VERSION ""

NS_ :

BS_:

BU_:

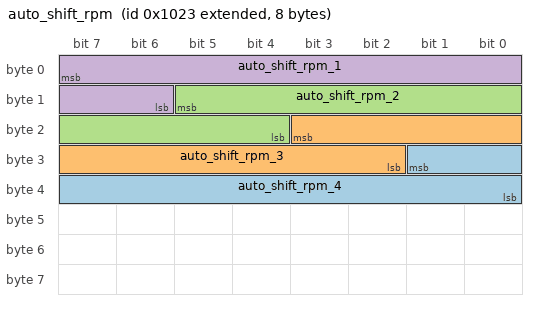
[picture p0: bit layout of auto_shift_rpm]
BO_ 2147487779 auto_shift_rpm: 8 Vector__XXX
 SG_ auto_shift_rpm_4 : 25|10@0+ (12,10000) [10000|22276] "RPM" Vector__XXX
 SG_ auto_shift_rpm_3 : 19|10@0+ (12,10000) [10000|22276] "RPM" Vector__XXX
 SG_ auto_shift_rpm_2 : 13|10@0+ (12,10000) [10000|22276] "RPM" Vector__XXX
 SG_ auto_shift_rpm_1 : 7|10@0+ (12,10000) [10000|22276] "RPM" Vector__XXX

BO_ 2147487776 servo: 5 Vector__XXX
 SG_ servo_pot : 27|12@0+ (0.00122100122,0) [0|0] "v" Vector__XXX
 SG_ servo_position : 23|12@0+ (1,0) [0|0] "us" Vector__XXX

BO_ 2147487777 settings: 8 Vector__XXX
 SG_ auto_shift : 47|1@0+ (1,0) [0|0] "boolean" Vector__XXX

BA_DEF_ BO_  "GenMsgCycleTime" INT 0 65535;
BA_DEF_DEF_  "GenMsgCycleTime" 0;
BA_ "GenMsgCycleTime" BO_ 2147487779 1000;
BA_ "GenMsgCycleTime" BO_ 2147487776 20;
BA_ "GenMsgCycleTime" BO_ 2147487777 200;
